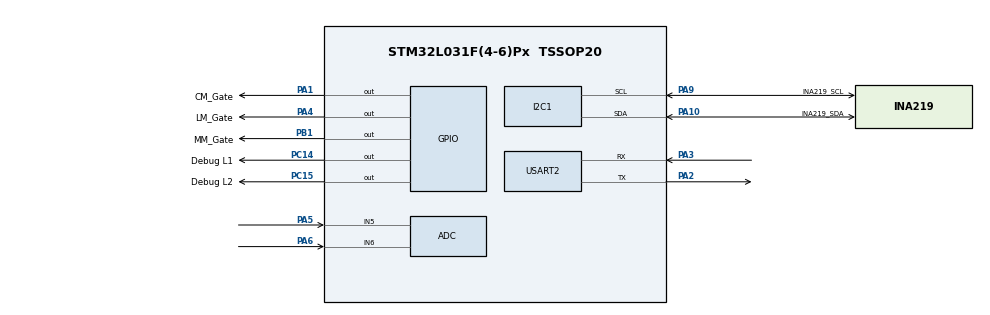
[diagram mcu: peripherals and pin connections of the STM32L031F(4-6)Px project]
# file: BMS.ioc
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I2C1.Timing=0x00707CBB
Mcu.Family=STM32L0
Mcu.Name=STM32L031F(4-6)Px
Mcu.Package=TSSOP20
PA0-CK_IN.Mode=HSE-External-Clock-Source-for-LittleNemo
PA0-CK_IN.Signal=RCC_CK_IN
PA1.GPIO_Label=CM_Gate
PA1.Signal=GPIO_Output
PA10.GPIO_Label=INA219_SDA
PA10.Mode=I2C
PA10.Signal=I2C1_SDA
PA13.Mode=Serial_Wire
PA13.Signal=SYS_SWDIO
PA14.Mode=Serial_Wire
PA14.Signal=SYS_SWCLK
PA2.Mode=Asynchronous
PA2.Signal=USART2_TX
PA3.Mode=Asynchronous
PA3.Signal=USART2_RX
PA4.GPIO_Label=LM_Gate
PA4.Signal=GPIO_Output
PA5.Mode=IN5
PA5.Signal=ADC_IN5
PA6.Mode=IN6
PA6.Signal=ADC_IN6
PA9.GPIO_Label=INA219_SCL
PA9.Mode=I2C
PA9.Signal=I2C1_SCL
PB1.GPIO_Label=MM_Gate
PB1.Signal=GPIO_Output
PC14-OSC32_IN.GPIO_Label=Debug L1
PC14-OSC32_IN.Signal=GPIO_Output
PC15-OSC32_OUT.GPIO_Label=Debug L2
PC15-OSC32_OUT.Signal=GPIO_Output
ProjectManager.HeapSize=0x200
ProjectManager.StackSize=0x400
ProjectManager.TargetToolchain=STM32CubeIDE
RCC.AHBFreq_Value=32000000
RCC.APB1Freq_Value=32000000
RCC.APB1TimFreq_Value=32000000
RCC.APB2Freq_Value=32000000
RCC.APB2TimFreq_Value=32000000
RCC.HCLKFreq_Value=32000000
RCC.HSE_VALUE=12000000
RCC.HSI16_VALUE=16000000
RCC.HSI_VALUE=16000000
RCC.LSE_VALUE=32768
RCC.MSI_VALUE=2097000
RCC.PLLDIV=RCC_PLLDIV_3
RCC.PLLMUL=RCC_PLLMUL_8
RCC.PLLSourceVirtual=RCC_PLLSOURCE_HSE
RCC.SYSCLKFreq_VALUE=32000000
RCC.SYSCLKSource=RCC_SYSCLKSOURCE_PLLCLK
RCC.VCOOutputFreq_Value=96000000
USART2.VirtualMode-Asynchronous=VM_ASYNC
board=custom

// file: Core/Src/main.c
/* USER CODE BEGIN Header */
/**
  ******************************************************************************
  * @file           : main.c
  * @brief          : Main program body
  ******************************************************************************
  * @attention
  *
  * Copyright (c) 2023 STMicroelectronics.
  * All rights reserved.
  *
  * This software is licensed under terms that can be found in the LICENSE file
  * in the root directory of this software component.
  * If no LICENSE file comes with this software, it is provided AS-IS.
  *
  ******************************************************************************
  */
/* USER CODE END Header */
#include "main.h"
#include "adc.h"
#include "i2c.h"
#include "usart.h"
#include "gpio.h"

/* USER CODE BEGIN PTD */
int _write(int file, char* p, int len)
{
	for(int i = 0; i < len; i++)
	{
		LL_USART_TransmitData8(USART2, *(p + i));
		LL_mDelay(1);
	}
	return len;
}

/* USER CODE END PTD */

void SystemClock_Config(void);

int main(void)
{

  /* MCU Configuration--------------------------------------------------------*/

  /* Reset of all peripherals, Initializes the Flash interface and the Systick. */
  LL_APB2_GRP1_EnableClock(LL_APB2_GRP1_PERIPH_SYSCFG);
  LL_APB1_GRP1_EnableClock(LL_APB1_GRP1_PERIPH_PWR);

  /* SysTick_IRQn interrupt configuration */
  NVIC_SetPriority(SysTick_IRQn, 3);

  /* Configure the system clock */
  SystemClock_Config();

  /* Initialize all configured peripherals */
  MX_GPIO_Init();
  MX_ADC_Init();
  MX_I2C1_Init();
  MX_USART2_UART_Init();
  /* USER CODE BEGIN 2 */
//  printf("BMS UART Test\n");
//  LL_mDelay(1000);
  uint8_t data[10] = {0x77, 0x01, 0x02, 0x03, 0x04, 0x05, 0x06, 0x07, 0x08, 0x09};

  /* USER CODE END 2 */

  /* Infinite loop */
  /* USER CODE BEGIN WHILE */
  while (1)
  {
	  for(int i = 0; i < 9; i++)
	  {
		  LL_GPIO_TogglePin(GPIOC, LL_GPIO_PIN_14);
		  printf("%x\n", data[i]);
		  LL_mDelay(1000);
	  }
    /* USER CODE END WHILE */

  }
}

void SystemClock_Config(void)
{
  LL_FLASH_SetLatency(LL_FLASH_LATENCY_1);
  while(LL_FLASH_GetLatency()!= LL_FLASH_LATENCY_1)
  {
  }
  LL_PWR_SetRegulVoltageScaling(LL_PWR_REGU_VOLTAGE_SCALE1);
  while (LL_PWR_IsActiveFlag_VOS() != 0)
  {
  }
  LL_RCC_HSE_EnableBypass();
  LL_RCC_HSE_Enable();

   /* Wait till HSE is ready */
  while(LL_RCC_HSE_IsReady() != 1)
  {

  }
  LL_RCC_PLL_ConfigDomain_SYS(LL_RCC_PLLSOURCE_HSE, LL_RCC_PLL_MUL_8, LL_RCC_PLL_DIV_3);
  LL_RCC_PLL_Enable();

   /* Wait till PLL is ready */
  while(LL_RCC_PLL_IsReady() != 1)
  {

  }
  LL_RCC_SetAHBPrescaler(LL_RCC_SYSCLK_DIV_1);
  LL_RCC_SetAPB1Prescaler(LL_RCC_APB1_DIV_1);
  LL_RCC_SetAPB2Prescaler(LL_RCC_APB2_DIV_1);
  LL_RCC_SetSysClkSource(LL_RCC_SYS_CLKSOURCE_PLL);

   /* Wait till System clock is ready */
  while(LL_RCC_GetSysClkSource() != LL_RCC_SYS_CLKSOURCE_STATUS_PLL)
  {

  }

  LL_Init1msTick(32000000);

  LL_SetSystemCoreClock(32000000);
  LL_RCC_SetUSARTClockSource(LL_RCC_USART2_CLKSOURCE_PCLK1);
  LL_RCC_SetI2CClockSource(LL_RCC_I2C1_CLKSOURCE_PCLK1);
}

void Error_Handler(void)
{
  __disable_irq();
  while (1)
  {
  }
}
